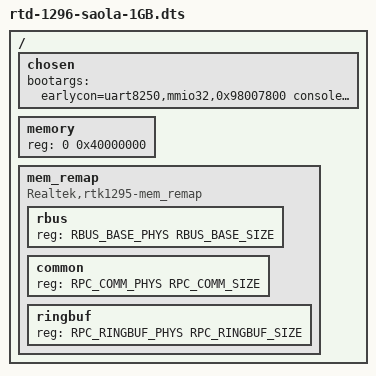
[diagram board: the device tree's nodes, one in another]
/dts-v1/;
#define CONFIG_ARCH_RTD129X
#include "../../../../../include/soc/realtek/memory.h"

/memreserve/ SYS_BOOTCODE_MEMBASE       SYS_BOOTCODE_MEMSIZE        ; /* 0x00000000 ~ 0x00030000 */
/memreserve/ RPC_COMM_PHYS              RPC_COMM_SIZE               ; /* 0x0001f000 ~ 0x0001ffff */
/memreserve/ ACPU_FIREWARE_PHYS         ACPU_FIREWARE_SIZE          ; /* 0x01b00000 ~ 0x01efffff */
/memreserve/ RPC_RINGBUF_PHYS           RPC_RINGBUF_SIZE            ; /* 0x01ffe000 ~ 0x02001fff */
/memreserve/ ACPU_IDMEM_PHYS            ACPU_IDMEM_SIZE             ; /* 0x10000000 ~ 0x10013fff */

#include "rtd-1296-saola-common.dtsi"

/ {
	chosen {
		bootargs = "earlycon=uart8250,mmio32,0x98007800 console=ttyS0,115200 loglevel=7";
	};

	memory {
		device_type = "memory";
		reg = <0 0x40000000>;	/* 1024 MB */
	};

	mem_remap {
        compatible = "Realtek,rtk1295-mem_remap";
        #address-cells = <1>;
        #size-cells = <1>;
        ranges;
        rbus {
            reg = <RBUS_BASE_PHYS RBUS_BASE_SIZE>;
        };
        common {
            reg = <RPC_COMM_PHYS RPC_COMM_SIZE>;
        };
        ringbuf {
            reg = <RPC_RINGBUF_PHYS RPC_RINGBUF_SIZE>;
        };
    };
};
